VERSION ""

NS_ :

BS_:

BU_:

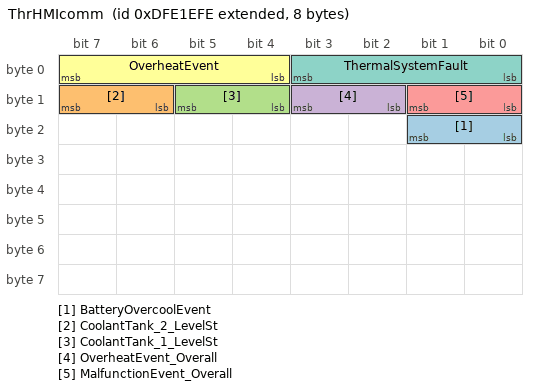
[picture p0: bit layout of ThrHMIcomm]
BO_ 2382241534 ThrHMIcomm: 8 Vector__XXX
 SG_ BatteryOvercoolEvent : 16|2@1+ (1,0) [0|3] "" Vector__XXX
 SG_ CoolantTank_2_LevelSt : 14|2@1+ (1,0) [0|0] "" Vector__XXX
 SG_ CoolantTank_1_LevelSt : 12|2@1+ (1,0) [0|0] "" Vector__XXX
 SG_ OverheatEvent_Overall : 10|2@1+ (1,0) [0|0] "" Vector__XXX
 SG_ MalfunctionEvent_Overall : 8|2@1+ (1,0) [0|0] "" Vector__XXX
 SG_ OverheatEvent : 4|4@1+ (1,0) [0|0] "" Vector__XXX
 SG_ ThermalSystemFault : 0|4@1+ (1,0) [0|0] "" Vector__XXX

CM_ "$File: //depot/auto/dbc/Software_Modules/Thermal_System/VanThermal/0.7.0.0/VanThermal.dbc $
$Change: 215785 $
$DateTime: 2024/08/14 10:39:06 $
$Revision: #1 $";
BA_DEF_ SG_  "SigType" ENUM  "Default","Range","RangeSigned","ASCII","Discrete","Control","ReferencePGN","DTC","StringDelimiter","StringLength","StringLengthControl","MessageCounter","MessageChecksum";
BA_DEF_ SG_  "GenSigEVName" STRING ;
BA_DEF_ SG_  "GenSigILSupport" ENUM  "No","Yes";
BA_DEF_ SG_  "GenSigSendType" ENUM  "Cyclic","OnWrite","OnWriteWithRepetition","OnChange","OnChangeWithRepetition","IfActive","IfActiveWithRepetition","NoSigSendType";
BA_DEF_ SG_  "GenSigStartValue" INT 0 2147483647;
BA_DEF_ BO_  "GenMsgILSupport" ENUM  "No","Yes";
BA_DEF_ BU_  "NmStationAddress" INT 0 255;
BA_DEF_ BO_  "GenMsgSendType" ENUM  "cyclic","NotUsed","IfActive","NotUsed","NotUsed","NotUsed","NotUsed","NotUsed","noMsgSendType";
BA_DEF_ BO_  "GenMsgRequestable" INT 0 1;
BA_DEF_ BO_  "GenMsgCycleTime" INT 0 3600000;
BA_DEF_ BO_  "Producer" STRING ;
BA_DEF_  "DBName" STRING ;
BA_DEF_  "BusType" STRING ;
BA_DEF_  "ProtocolType" STRING ;
BA_DEF_ BO_  "VFrameFormat" ENUM  "StandardCAN","ExtendedCAN","reserved","J1939PG";
BA_DEF_DEF_  "SigType" "Default";
BA_DEF_DEF_  "GenSigEVName" "Env@Nodename_@Signame";
BA_DEF_DEF_  "GenSigILSupport" "Yes";
BA_DEF_DEF_  "GenSigSendType" "NoSigSendType";
BA_DEF_DEF_  "GenSigStartValue" 0;
BA_DEF_DEF_  "GenMsgILSupport" "Yes";
BA_DEF_DEF_  "NmStationAddress" 254;
BA_DEF_DEF_  "GenMsgSendType" "noMsgSendType";
BA_DEF_DEF_  "GenMsgRequestable" 1;
BA_DEF_DEF_  "GenMsgCycleTime" 0;
BA_DEF_DEF_  "Producer" "TMS";
BA_DEF_DEF_  "DBName" "VanThermal";
BA_DEF_DEF_  "BusType" "CAN";
BA_DEF_DEF_  "ProtocolType" "J1939";
BA_DEF_DEF_  "VFrameFormat" "J1939PG";
BA_ "GenMsgSendType" BO_ 2382241534 0;
BA_ "GenMsgCycleTime" BO_ 2382241534 500;
BA_ "GenSigStartValue" SG_ 2382241534 BatteryOvercoolEvent 3;
BA_ "GenSigStartValue" SG_ 2382241534 CoolantTank_2_LevelSt 3;
BA_ "GenSigStartValue" SG_ 2382241534 CoolantTank_1_LevelSt 3;
BA_ "GenSigStartValue" SG_ 2382241534 OverheatEvent_Overall 3;
BA_ "GenSigStartValue" SG_ 2382241534 MalfunctionEvent_Overall 3;
BA_ "GenSigStartValue" SG_ 2382241534 OverheatEvent 15;
BA_ "GenSigStartValue" SG_ 2382241534 ThermalSystemFault 15;
VAL_ 2382241534 BatteryOvercoolEvent 3 "Not Available" 2 "Error" 1 "On" 0 "Off" ;
VAL_ 2382241534 CoolantTank_2_LevelSt 3 "NA" 2 "Reserved" 1 "High" 0 "Low" ;
VAL_ 2382241534 CoolantTank_1_LevelSt 3 "NA" 2 "Reserved" 1 "High" 0 "Low" ;
VAL_ 2382241534 OverheatEvent_Overall 3 "Overheat_NA" 2 "Overheat_Error" 1 "Overheat_Detected" 0 "Overheat_Not_Detected" ;
VAL_ 2382241534 MalfunctionEvent_Overall 3 "NA" 2 "Critical_Event" 1 "Medium_Event" 0 "Not_Detected" ;
VAL_ 2382241534 OverheatEvent 15 "Overheat_NA" 14 "Overheat_Error" 6 "Overheat_Battery" 5 "Overheat_DCDC" 4 "Overheat_OBC" 3 "Overheat_Gearbox" 2 "Overheat_Motor" 1 "Overheat_Invertor" 0 "Overheat_Nothing" ;
VAL_ 2382241534 ThermalSystemFault 14 "ThrFlt_Error" 15 "ThrFlt_NA" 3 "ThrFlt_DeviceFault" 2 "ThrFlt_CAN_Comm" 1 "ThrFlt_AmbOORange" 0 "ThrFlt_Nothing" ;
